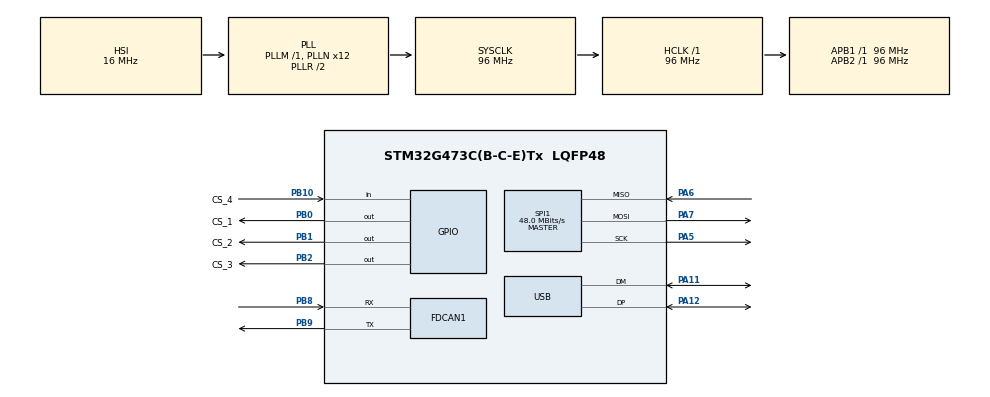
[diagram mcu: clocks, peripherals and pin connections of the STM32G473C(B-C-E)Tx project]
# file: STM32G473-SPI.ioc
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FDCAN1.AutoRetransmission=DISABLE
FDCAN1.ClockDivider=FDCAN_CLOCK_DIV1
FDCAN1.DataPrescaler=1
FDCAN1.DataSyncJumpWidth=1
FDCAN1.DataTimeSeg1=1
FDCAN1.DataTimeSeg2=1
FDCAN1.ExtFiltersNbr=0
FDCAN1.FrameFormat=FDCAN_FRAME_CLASSIC
FDCAN1.Mode=FDCAN_MODE_NORMAL
FDCAN1.NominalPrescaler=1
FDCAN1.NominalSyncJumpWidth=1
FDCAN1.NominalTimeSeg1=2
FDCAN1.NominalTimeSeg2=2
FDCAN1.ProtocolException=DISABLE
FDCAN1.StdFiltersNbr=0
FDCAN1.TransmitPause=DISABLE
FDCAN1.TxFifoQueueMode=FDCAN_TX_FIFO_OPERATION
Mcu.Family=STM32G4
Mcu.Name=STM32G473C(B-C-E)Tx
Mcu.Package=LQFP48
NVIC.PriorityGroup=NVIC_PRIORITYGROUP_4
NVIC.USB_LP_IRQn=true\:0\:0\:false\:false\:true\:false\:true
PA11.Mode=Device
PA11.Signal=USB_DM
PA12.Mode=Device
PA12.Signal=USB_DP
PA13.Mode=Serial_Wire
PA13.Signal=SYS_JTMS-SWDIO
PA14.Mode=Serial_Wire
PA14.Signal=SYS_JTCK-SWCLK
PA5.Mode=Full_Duplex_Master
PA5.Signal=SPI1_SCK
PA6.Mode=Full_Duplex_Master
PA6.Signal=SPI1_MISO
PA7.Mode=Full_Duplex_Master
PA7.Signal=SPI1_MOSI
PB0.GPIO_Label=CS_1
PB0.Signal=GPIO_Output
PB1.GPIO_Label=CS_2
PB1.Signal=GPIO_Output
PB10.GPIO_Label=CS_4
PB10.Signal=GPIO_Input
PB2.GPIO_Label=CS_3
PB2.Signal=GPIO_Output
PB8-BOOT0.Mode=FDCAN_Activate
PB8-BOOT0.Signal=FDCAN1_RX
PB9.Mode=FDCAN_Activate
PB9.Signal=FDCAN1_TX
PC14-OSC32_IN.Mode=LSE-External-Oscillator
PC14-OSC32_IN.Signal=RCC_OSC32_IN
PC15-OSC32_OUT.Mode=LSE-External-Oscillator
PC15-OSC32_OUT.Signal=RCC_OSC32_OUT
ProjectManager.HeapSize=0x200
ProjectManager.StackSize=0x400
ProjectManager.TargetToolchain=STM32CubeIDE
RCC.ADC12Freq_Value=96000000
RCC.ADC345Freq_Value=96000000
RCC.AHBFreq_Value=96000000
RCC.APB1Freq_Value=96000000
RCC.APB1TimFreq_Value=96000000
RCC.APB2Freq_Value=96000000
RCC.APB2TimFreq_Value=96000000
RCC.CortexFreq_Value=96000000
RCC.EXTERNAL_CLOCK_VALUE=12288000
RCC.HCLKFreq_Value=96000000
RCC.HSE_VALUE=8000000
RCC.HSI48_VALUE=48000000
RCC.HSI_VALUE=16000000
RCC.PLLN=12
RCC.PLLQ=RCC_PLLQ_DIV4
RCC.RTCClockSelection=RCC_RTCCLKSOURCE_LSE
RCC.SYSCLKFreq_VALUE=96000000
RCC.SYSCLKSource=RCC_SYSCLKSOURCE_PLLCLK
RCC.USBFreq_Value=48000000
RCC.VCOOutputFreq_Value=192000000
SPI1.BaudRatePrescaler=SPI_BAUDRATEPRESCALER_2
SPI1.CLKPhase=SPI_PHASE_1EDGE
SPI1.CLKPolarity=SPI_POLARITY_LOW
SPI1.CRCCalculation=SPI_CRCCALCULATION_DISABLE
SPI1.CalculateBaudRate=48.0 MBits/s
SPI1.DataSize=SPI_DATASIZE_8BIT
SPI1.Direction=SPI_DIRECTION_2LINES
SPI1.FirstBit=SPI_FIRSTBIT_MSB
SPI1.Mode=SPI_MODE_MASTER
SPI1.NSS=SPI_NSS_SOFT
SPI1.NSSPMode=SPI_NSS_PULSE_ENABLE
SPI1.TIMode=SPI_TIMODE_DISABLE
SPI1.VirtualType=VM_MASTER
USB.DeviceSpeed=PCD_SPEED_FULL
USB.Sof_enable=DISABLE
USB.battery_charging_enable=DISABLE
USB.low_power_enable=DISABLE
USB.lpm_enable=DISABLE
USB.phy_itface=PCD_PHY_EMBEDDED
USB_DEVICE.APP_RX_DATA_SIZE=1000
USB_DEVICE.APP_TX_DATA_SIZE=1000
USB_DEVICE.CLASS_NAME_FS=CDC
USB_DEVICE.CONFIGURATION_STRING_CDC_FS=CDC Config
USB_DEVICE.INTERFACE_STRING_CDC_FS=CDC Interface
USB_DEVICE.LANGID_STRING=1033
USB_DEVICE.MANUFACTURER_STRING=STMicroelectronics
USB_DEVICE.PID_CDC_FS=22336
USB_DEVICE.PRODUCT_STRING_CDC_FS=STM32 Virtual ComPort
USB_DEVICE.USBD_DEBUG_LEVEL=0
USB_DEVICE.USBD_LPM_ENABLED=1
USB_DEVICE.USBD_MAX_NUM_CONFIGURATION=1
USB_DEVICE.USBD_MAX_NUM_INTERFACES=1
USB_DEVICE.USBD_MAX_STR_DESC_SIZ=512
USB_DEVICE.USBD_SELF_POWERED=1
USB_DEVICE.VID=1155
USB_DEVICE.VirtualMode=Cdc
USB_DEVICE.VirtualModeFS=Cdc_FS
VP_RTC_VS_RTC_Activate.Mode=RTC_Enabled
VP_SYS_VS_DBSignals.Mode=DisableDeadBatterySignals
VP_USB_DEVICE_VS_USB_DEVICE_CDC_FS.Mode=CDC_FS
board=custom

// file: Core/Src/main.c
/* USER CODE BEGIN Header */
/**
  ******************************************************************************
  * @file           : main.c
  * @brief          : Main program body
  ******************************************************************************
  * @attention
  *
  * <h2><center>&copy; Copyright (c) 2021 STMicroelectronics.
  * All rights reserved.</center></h2>
  *
  * This software component is licensed by ST under Ultimate Liberty license
  * SLA0044, the "License"; You may not use this file except in compliance with
  * the License. You may obtain a copy of the License at:
  *                             www.st.com/SLA0044
  *
  ******************************************************************************
  */
/* USER CODE END Header */
#include "main.h"
#include "fdcan.h"
#include "rtc.h"
#include "spi.h"
#include "usb_device.h"
#include "gpio.h"

/* USER CODE BEGIN Includes */
#include "MAX31856drv.h"
#include "usbd_cdc_if.h"

/* USER CODE END Includes */

void SystemClock_Config(void);

int main(void)
{

  /* MCU Configuration--------------------------------------------------------*/

  /* Reset of all peripherals, Initializes the Flash interface and the Systick. */
  HAL_Init();

  /* Configure the system clock */
  SystemClock_Config();

  /* Initialize all configured peripherals */
  MX_GPIO_Init();
  MX_FDCAN1_Init();
  MX_SPI1_Init();
  MX_USB_Device_Init();
  MX_RTC_Init();
  /* USER CODE BEGIN 2 */

  maxim_31856_init();

  /* USER CODE END 2 */

  /* Infinite loop */
  while (1)
  {

    /* USER CODE BEGIN 3 */
	  maxim_start_conversion( One_Shot_Conversion );
	  HAL_Delay(1000);
	  maxim_31856_read_register( 1 );
	  CDC_Transmit_FS( (uint8_t*)"Debug", 8);
  }
  /* USER CODE END 3 */
}

void SystemClock_Config(void)
{
  RCC_OscInitTypeDef RCC_OscInitStruct = {0};
  RCC_ClkInitTypeDef RCC_ClkInitStruct = {0};
  RCC_PeriphCLKInitTypeDef PeriphClkInit = {0};

  /** Configure the main internal regulator output voltage
  */
  HAL_PWREx_ControlVoltageScaling(PWR_REGULATOR_VOLTAGE_SCALE1);
  /** Configure LSE Drive Capability
  */
  HAL_PWR_EnableBkUpAccess();
  __HAL_RCC_LSEDRIVE_CONFIG(RCC_LSEDRIVE_LOW);
  /** Initializes the RCC Oscillators according to the specified parameters
  * in the RCC_OscInitTypeDef structure.
  */
  RCC_OscInitStruct.OscillatorType = RCC_OSCILLATORTYPE_HSI|RCC_OSCILLATORTYPE_LSE;
  RCC_OscInitStruct.LSEState = RCC_LSE_ON;
  RCC_OscInitStruct.HSIState = RCC_HSI_ON;
  RCC_OscInitStruct.HSICalibrationValue = RCC_HSICALIBRATION_DEFAULT;
  RCC_OscInitStruct.PLL.PLLState = RCC_PLL_ON;
  RCC_OscInitStruct.PLL.PLLSource = RCC_PLLSOURCE_HSI;
  RCC_OscInitStruct.PLL.PLLM = RCC_PLLM_DIV1;
  RCC_OscInitStruct.PLL.PLLN = 12;
  RCC_OscInitStruct.PLL.PLLP = RCC_PLLP_DIV2;
  RCC_OscInitStruct.PLL.PLLQ = RCC_PLLQ_DIV4;
  RCC_OscInitStruct.PLL.PLLR = RCC_PLLR_DIV2;
  if (HAL_RCC_OscConfig(&RCC_OscInitStruct) != HAL_OK)
  {
    Error_Handler();
  }
  /** Initializes the CPU, AHB and APB buses clocks
  */
  RCC_ClkInitStruct.ClockType = RCC_CLOCKTYPE_HCLK|RCC_CLOCKTYPE_SYSCLK
                              |RCC_CLOCKTYPE_PCLK1|RCC_CLOCKTYPE_PCLK2;
  RCC_ClkInitStruct.SYSCLKSource = RCC_SYSCLKSOURCE_PLLCLK;
  RCC_ClkInitStruct.AHBCLKDivider = RCC_SYSCLK_DIV1;
  RCC_ClkInitStruct.APB1CLKDivider = RCC_HCLK_DIV1;
  RCC_ClkInitStruct.APB2CLKDivider = RCC_HCLK_DIV1;

  if (HAL_RCC_ClockConfig(&RCC_ClkInitStruct, FLASH_LATENCY_2) != HAL_OK)
  {
    Error_Handler();
  }
  /** Initializes the peripherals clocks
  */
  PeriphClkInit.PeriphClockSelection = RCC_PERIPHCLK_RTC|RCC_PERIPHCLK_USB
                              |RCC_PERIPHCLK_FDCAN;
  PeriphClkInit.FdcanClockSelection = RCC_FDCANCLKSOURCE_PCLK1;
  PeriphClkInit.UsbClockSelection = RCC_USBCLKSOURCE_PLL;
  PeriphClkInit.RTCClockSelection = RCC_RTCCLKSOURCE_LSE;
  if (HAL_RCCEx_PeriphCLKConfig(&PeriphClkInit) != HAL_OK)
  {
    Error_Handler();
  }
}

void Error_Handler(void)
{
  __disable_irq();
  while (1)
  {
  }
}

/************************ (C) COPYRIGHT STMicroelectronics *****END OF FILE****/
